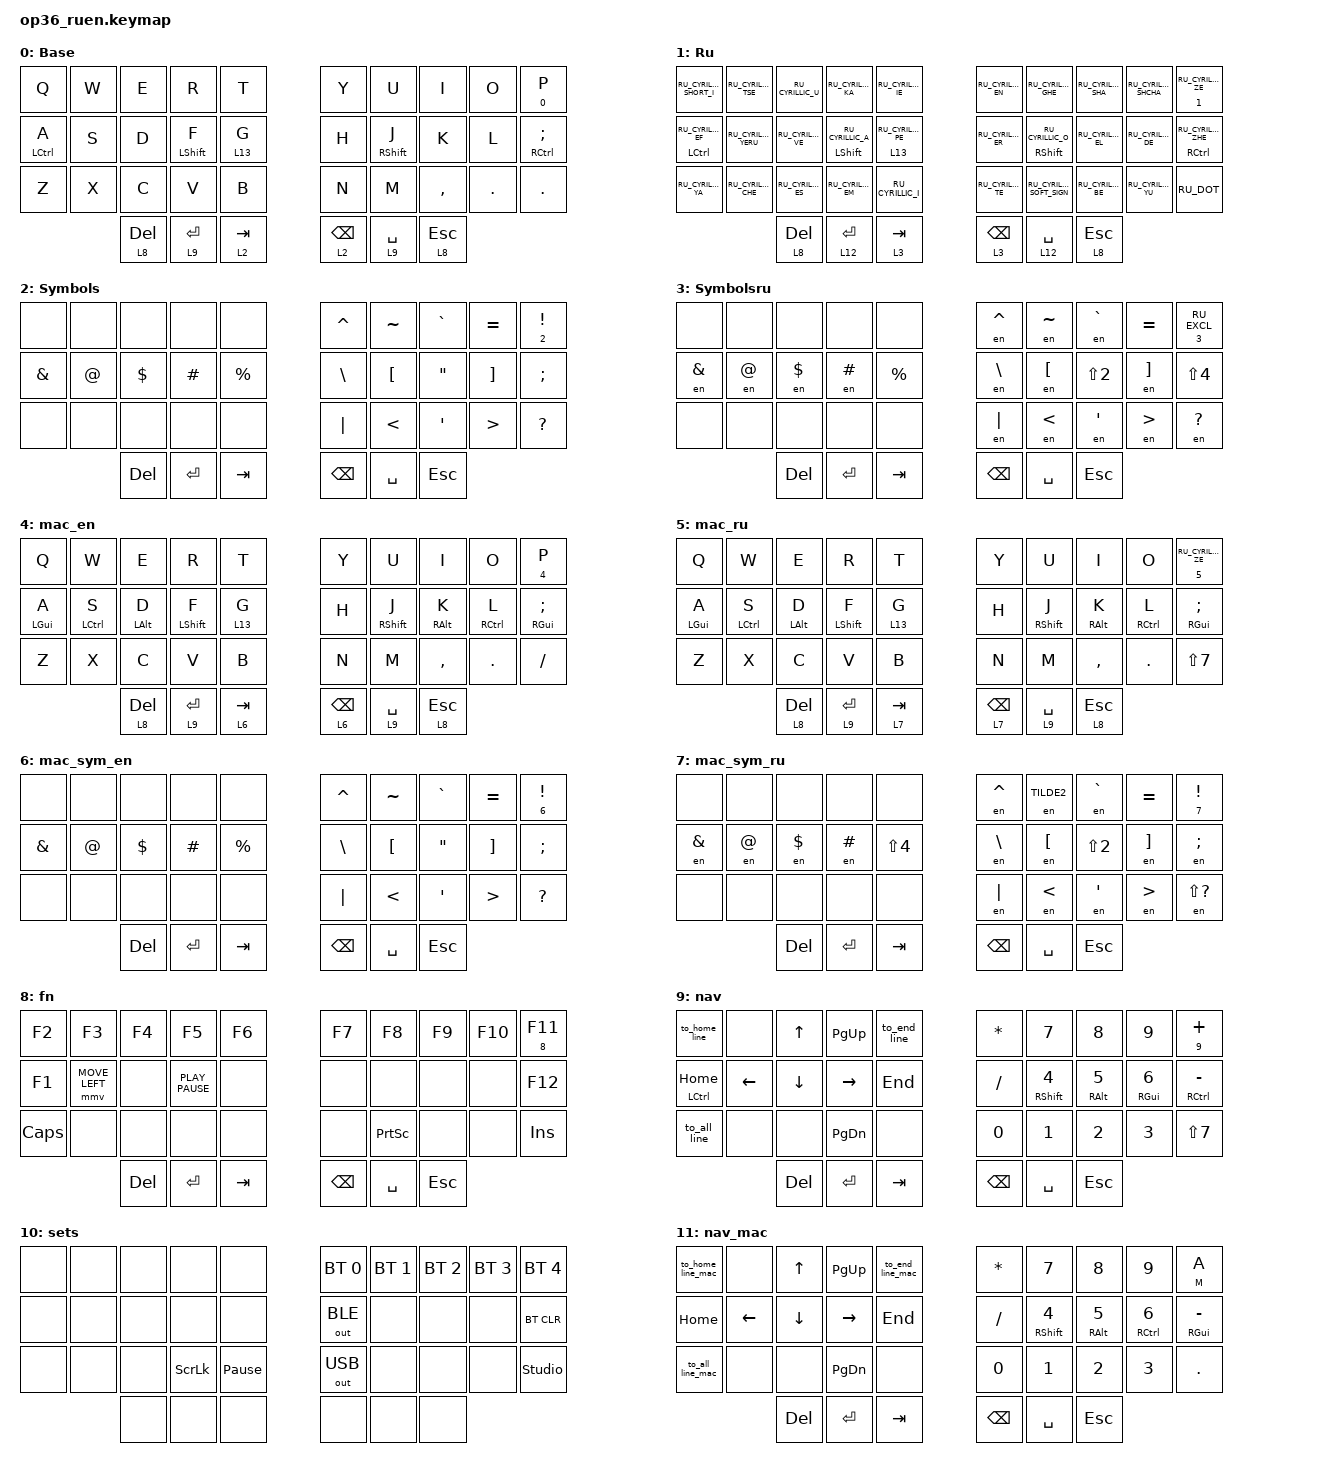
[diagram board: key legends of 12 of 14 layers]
#include "keys_ru.h"
#include "keys_ru.h"
#include <behaviors.dtsi>
#include <dt-bindings/zmk/bt.h>
#include <dt-bindings/zmk/keys.h>
#include <dt-bindings/zmk/outputs.h>
#include <dt-bindings/zmk/pointing.h>

&mt {
    quick-tap-ms = <200>;
    flavor = "tap-preferred";
    require-prior-idle-ms = <125>;
};

/ {
    behaviors {
        hml: home_row_mod_left {
            compatible = "zmk,behavior-hold-tap";
            #binding-cells = <2>;
            flavor = "balanced";
            require-prior-idle-ms = <100>;
            tapping-term-ms = <140>;
            quick-tap-ms = <120>;
            bindings = <&kp>, <&kp>;

            hold-trigger-key-positions = <5 6 7 8 9 15 16 17 18 19 25 26 27 28 29 33 34 35>;
            hold-trigger-on-release;
        };

        hmr: home_row_mod_right {
            compatible = "zmk,behavior-hold-tap";
            #binding-cells = <2>;
            flavor = "balanced";
            require-prior-idle-ms = <100>;
            tapping-term-ms = <140>;
            quick-tap-ms = <120>;
            bindings = <&kp>, <&kp>;

            hold-trigger-key-positions = <0 1 2 3 4 10 11 12 13 14 20 21 22 23 24 30 31 32>;
            hold-trigger-on-release;
        };
    };

    combos {
        compatible = "zmk,combos";

        kha {
            bindings = <&kp RU_CYRILLIC_HA>;
            key-positions = <8 7>;
            layers = <1 5>;
        };

        hrdsgn {
            bindings = <&kp RU_CYRILLIC_HARD_SIGN>;
            key-positions = <6 9>;
            layers = <1 5>;
        };

        cmben {
            bindings = <&layer_en>;
            key-positions = <2 1>;
            layers = <1>;
        };

        cmbru {
            bindings = <&layer_ru>;
            key-positions = <2 1>;
            layers = <0>;
        };

        to_mac {
            bindings = <&mac_layer_en>;
            key-positions = <35 33>;
        };

        to_base {
            bindings = <&layer_en>;
            key-positions = <30 32>;
        };

        cmd_mac_ru {
            bindings = <&mac_layer_ru>;
            key-positions = <1 2>;
            layers = <4>;
        };

        cmd_mac_en {
            bindings = <&mac_layer_en>;
            key-positions = <1 2>;
            layers = <5>;
        };

        ru_io {
            bindings = <&kp RU_CYRILLIC_IO>;
            key-positions = <3 2>;
            layers = <1>;
        };

        mac_ru_io {
            bindings = <&kp BACKSLASH>;
            key-positions = <3 2>;
            layers = <7 5>;
        };

        ru_ea {
            bindings = <&kp SINGLE_QUOTE>;
            key-positions = <6 7>;
            layers = <1 5 3 7>;
        };

        colon_en {
            bindings = <&kp COLON>;
            key-positions = <16 17>;
            layers = <0 2 4 6>;
        };

        colon_ru {
            bindings = <&kp RU_COLON>;
            key-positions = <16 17>;
            layers = <1 3>;
        };

        comma_en {
            bindings = <&kp COMMA>;
            key-positions = <26 27>;
            layers = <0 2 4 6 9>;
        };

        comma_ru {
            bindings = <&kp LS(SLASH)>;
            key-positions = <26 27>;
            layers = <1 3 12>;
        };

        to_layer_en {
            bindings = <&to 0>;
            key-positions = <1 2 3>;
            layers = <1>;
        };

        to_layer_mac_en {
            bindings = <&to 4>;
            key-positions = <1 2 3>;
            layers = <5>;
        };

        brace_left_en {
            bindings = <&kp LEFT_BRACE>;
            key-positions = <16 7>;
            layers = <0 2 6 4>;
        };

        brace_right_en {
            bindings = <&kp RIGHT_BRACE>;
            key-positions = <6 17>;
            layers = <0 2 4 6>;
        };

        brace_left_ru {
            bindings = <&en LEFT_BRACE>;
            key-positions = <16 7>;
            layers = <1 3 5 7>;
        };

        brace_right_ru {
            bindings = <&en RIGHT_BRACE>;
            key-positions = <6 17>;
            layers = <1 3 5 7>;
        };

        br_left {
            bindings = <&kp LS(NUMBER_9)>;
            key-positions = <26 17>;
        };

        br_right {
            bindings = <&kp LS(NUMBER_0)>;
            key-positions = <27 16>;
        };

        underscore {
            bindings = <&kp UNDER>;
            key-positions = <6 15>;
        };

        comma_mac_ru {
            bindings = <&kp LS(NUMBER_6)>;
            key-positions = <26 27>;
            layers = <5 7>;
        };

        colon_mac_ru {
            bindings = <&kp LS(NUMBER_5)>;
            key-positions = <16 17>;
            layers = <5 7>;
        };

        lt10 {
            bindings = <&mo 10>;
            key-positions = <30 31>;
        };

        Lalt {
            bindings = <&kp LEFT_ALT>;
            key-positions = <11 12>;
        };

        Ralt {
            bindings = <&kp RIGHT_ALT>;
            key-positions = <17 18>;
        };

        Lgui {
            bindings = <&kp LEFT_GUI>;
            key-positions = <21 22>;
        };

        Rgui {
            bindings = <&kp RIGHT_GUI>;
            key-positions = <27 28>;
        };
    };

    macros {
        to_ru: to_ru {
            compatible = "zmk,behavior-macro";
            #binding-cells = <0>;
            bindings = <&kp LG(SPACE)>;
            label = "TO_RU";
            wait-ms = <0>;
            tap-ms = <30>;
        };

        to_en: to_en {
            compatible = "zmk,behavior-macro";
            #binding-cells = <0>;
            bindings = <&kp LG(SPACE)>;
            label = "TO_EN";
            wait-ms = <0>;
            tap-ms = <30>;
        };

        layer_en: layer_en {
            compatible = "zmk,behavior-macro";
            #binding-cells = <0>;
            bindings = <&to 0 &to_en>;
            label = "LAYER_EN";
            wait-ms = <0>;
            tap-ms = <30>;
        };

        layer_ru: layer_ru {
            compatible = "zmk,behavior-macro";
            #binding-cells = <0>;
            bindings = <&to 1 &to_ru>;
            label = "LAYER_RU";
            tap-ms = <30>;
            wait-ms = <0>;
        };

        en: en {
            compatible = "zmk,behavior-macro-one-param";
            #binding-cells = <1>;
            bindings =
                <&to_en>,
                <&macro_press>,
                <&macro_param_1to1 &kp MACRO_PLACEHOLDER>,
                <&macro_pause_for_release>,
                <&macro_release>,
                <&macro_param_1to1 &kp MACRO_PLACEHOLDER>,
                <&macro_tap>,
                <&to_ru>;

            label = "EN";
            wait-ms = <0>;
            tap-ms = <30>;
        };

        mac_layer_ru: mac_layer_ru {
            compatible = "zmk,behavior-macro";
            #binding-cells = <0>;
            bindings = <&to 5 &to_ru>;
            label = "MAC_LAYER_RU";
        };

        mac_layer_en: mac_layer_en {
            compatible = "zmk,behavior-macro";
            #binding-cells = <0>;
            bindings = <&to 4 &to_en>;
            label = "MAC_LAYER_EN";
        };

        to_home_line: to_home_line {
            compatible = "zmk,behavior-macro";
            #binding-cells = <0>;
            bindings = <&kp LS(HOME)>, <&macro_wait_time 50>, <&kp LC(C)>;

            label = "TO_HOME_LINE";
        };

        to_home_line_mac: to_home_line_mac {
            compatible = "zmk,behavior-macro";
            #binding-cells = <0>;
            bindings = <&kp LS(HOME)>, <&macro_wait_time 50>, <&kp LG(C)>;

            label = "TO_HOME_LINE_MAC";
        };

        to_end_line: to_end_line {
            compatible = "zmk,behavior-macro";
            #binding-cells = <0>;
            bindings = <&kp LS(END)>, <&macro_wait_time 50>, <&kp LC(C)>;

            label = "TO_END_LINE";
        };

        to_end_line_mac: to_end_line_mac {
            compatible = "zmk,behavior-macro";
            #binding-cells = <0>;
            bindings = <&kp LS(END)>, <&macro_wait_time 50>, <&kp LG(C)>;

            label = "TO_END_LINE_MAC";
        };

        to_all_line: to_all_line {
            compatible = "zmk,behavior-macro";
            #binding-cells = <0>;
            bindings =
                <&kp HOME>,
                <&macro_wait_time 50>,
                <&kp LS(END)>,
                <&macro_wait_time 50>,
                <&kp LC(C)>;

            label = "TO_ALL_LINE";
        };

        to_all_line_mac: to_all_line_mac {
            compatible = "zmk,behavior-macro";
            #binding-cells = <0>;
            bindings =
                <&kp HOME>,
                <&macro_wait_time 50>,
                <&kp LS(END)>,
                <&macro_wait_time 50>,
                <&kp LG(C)>;

            label = "TO_ALL_LINE_MAC";
        };

        code_block: code_block {
            compatible = "zmk,behavior-macro";
            #binding-cells = <0>;
            bindings =
                <&kp GRAVE &kp GRAVE &kp GRAVE>,
                <&macro_wait_time 50>,
                <&kp ENTER>,
                <&macro_wait_time 50>,
                <&kp GRAVE &kp GRAVE &kp GRAVE>,
                <&macro_wait_time 50>,
                <&kp UP>;

            label = "CODE_BLOCK";
        };
    };

    keymap {
        compatible = "zmk,keymap";

        en {
            bindings = <
  &kp Q         &kp W  &kp E  &kp R              &kp T                                      &kp Y        &kp U          &kp I      &kp O    &mt NUMBER_0 P
  &hml LCTRL A  &kp S  &kp D  &hml LEFT_SHIFT F  &lt 13 G                                   &kp H        &hmr RSHIFT J  &kp K      &kp L    &hmr RCTRL SEMICOLON
  &kp Z         &kp X  &kp C  &kp V              &kp B                                      &kp N        &kp M          &kp COMMA  &kp DOT  &kp DOT
                              &lt 8 DEL          &lt 9 ENTER  &lt 2 TAB    &lt 2 BACKSPACE  &lt 9 SPACE  &lt 8 ESC
            >;

            display-name = "Base";
        };

        ru {
            bindings = <
  &kp RU_CYRILLIC_SHORT_I    &kp RU_CYRILLIC_TSE   &kp RU_CYRILLIC_U   &kp RU_CYRILLIC_KA         &kp RU_CYRILLIC_IE                                   &kp RU_CYRILLIC_EN  &kp RU_CYRILLIC_GHE             &kp RU_CYRILLIC_SHA  &kp RU_CYRILLIC_SHCHA  &mt NUMBER_1 RU_CYRILLIC_ZE
  &hml LCTRL RU_CYRILLIC_EF  &kp RU_CYRILLIC_YERU  &kp RU_CYRILLIC_VE  &hml LSHIFT RU_CYRILLIC_A  &lt 13 RU_CYRILLIC_PE                                &kp RU_CYRILLIC_ER  &hmr RIGHT_SHIFT RU_CYRILLIC_O  &kp RU_CYRILLIC_EL   &kp RU_CYRILLIC_DE     &hmr RCTRL RU_CYRILLIC_ZHE
  &kp RU_CYRILLIC_YA         &kp RU_CYRILLIC_CHE   &kp RU_CYRILLIC_ES  &kp RU_CYRILLIC_EM         &kp RU_CYRILLIC_I                                    &kp RU_CYRILLIC_TE  &kp RU_CYRILLIC_SOFT_SIGN       &kp RU_CYRILLIC_BE   &kp RU_CYRILLIC_YU     &kp RU_DOT
                                                                       &lt 8 DEL                  &lt 12 ENTER           &lt 3 TAB    &lt 3 BACKSPACE  &lt 12 SPACE        &lt 8 ESC
            >;

            display-name = "Ru";
        };

        sym_en {
            bindings = <
  &none          &none        &none       &none     &none                                  &kp CARET      &kp TILDE         &kp GRAVE          &kp EQUAL          &mt NUMBER_2 EXCLAMATION
  &kp AMPERSAND  &kp AT_SIGN  &kp DOLLAR  &kp HASH  &kp PERCENT                            &kp BACKSLASH  &kp LEFT_BRACKET  &kp DOUBLE_QUOTES  &kp RIGHT_BRACKET  &kp SEMICOLON
  &none          &none        &none       &none     &none                                  &kp PIPE       &kp LESS_THAN     &kp APOSTROPHE     &kp GREATER_THAN   &kp QUESTION
                                          &kp DEL   &kp ENTER    &kp TAB    &kp BACKSPACE  &kp SPACE      &kp ESC
            >;

            display-name = "Symbols";
        };

        sym_ru {
            bindings = <
  &none          &none        &none       &none     &none                                  &en CARET      &en TILDE         &en GRAVE         &kp EQUAL          &mt NUMBER_3 RU_EXCL
  &en AMPERSAND  &en AT_SIGN  &en DOLLAR  &en HASH  &kp PERCENT                            &en BACKSLASH  &en LEFT_BRACKET  &kp LS(NUMBER_2)  &en RIGHT_BRACKET  &kp LS(NUMBER_4)
  &none          &none        &none       &none     &none                                  &en PIPE       &en LESS_THAN     &en SINGLE_QUOTE  &en GREATER_THAN   &en QUESTION
                                          &kp DEL   &kp ENTER    &kp TAB    &kp BACKSPACE  &kp SPACE      &kp ESC
            >;

            display-name = "Symbolsru";
        };

        mac_en {
            bindings = <
  &kp Q            &kp W         &kp E            &kp R              &kp T                                      &kp Y        &kp U               &kp I             &kp O         &mt NUMBER_4 P
  &hml LEFT_GUI A  &hml LCTRL S  &hml LEFT_ALT D  &hml LEFT_SHIFT F  &lt 13 G                                   &kp H        &hmr RIGHT_SHIFT J  &hmr RIGHT_ALT K  &hmr RCTRL L  &hmr RIGHT_GUI SEMI
  &kp Z            &kp X         &kp C            &kp V              &kp B                                      &kp N        &kp M               &kp COMMA         &kp DOT       &kp FSLH
                                                  &lt 8 DEL          &lt 9 ENTER  &lt 6 TAB    &lt 6 BACKSPACE  &lt 9 SPACE  &lt 8 ESC
            >;
        };

        mac_ru {
            bindings = <
  &kp Q            &kp W         &kp E            &kp R              &kp T                                      &kp Y        &kp U               &kp I             &kp O         &mt NUMBER_5 RU_CYRILLIC_ZE
  &hml LEFT_GUI A  &hml LCTRL S  &hml LEFT_ALT D  &hml LEFT_SHIFT F  &lt 13 G                                   &kp H        &hmr RIGHT_SHIFT J  &hmr RIGHT_ALT K  &hmr RCTRL L  &hmr RIGHT_GUI SEMI
  &kp Z            &kp X         &kp C            &kp V              &kp B                                      &kp N        &kp M               &kp COMMA         &kp DOT       &kp LS(NUMBER_7)
                                                  &lt 8 DEL          &lt 9 ENTER  &lt 7 TAB    &lt 7 BACKSPACE  &lt 9 SPACE  &lt 8 ESC
            >;
        };

        mac_sym_en {
            bindings = <
  &none          &none        &none       &none     &none                                  &kp CARET      &kp TILDE         &kp GRAVE          &kp EQUAL          &mt NUMBER_6 EXCLAMATION
  &kp AMPERSAND  &kp AT_SIGN  &kp DOLLAR  &kp HASH  &kp PERCENT                            &kp BACKSLASH  &kp LEFT_BRACKET  &kp DOUBLE_QUOTES  &kp RIGHT_BRACKET  &kp SEMICOLON
  &none          &none        &none       &none     &none                                  &kp PIPE       &kp LESS_THAN     &kp APOSTROPHE     &kp GREATER_THAN   &kp QUESTION
                                          &kp DEL   &kp ENTER    &kp TAB    &kp BACKSPACE  &kp SPACE      &kp ESC
            >;
        };

        mac_sym_ru {
            bindings = <
  &none          &none        &none       &none     &none                                       &en CARET      &en TILDE2        &en GRAVE         &kp EQUAL          &mt NUMBER_7 EXCLAMATION
  &en AMPERSAND  &en AT_SIGN  &en DOLLAR  &en HASH  &kp LS(NUMBER_4)                            &en BACKSLASH  &en LEFT_BRACKET  &kp LS(NUMBER_2)  &en RIGHT_BRACKET  &en SEMICOLON
  &none          &none        &none       &none     &none                                       &en PIPE       &en LESS_THAN     &en SINGLE_QUOTE  &en GREATER_THAN   &en LS(QUESTION)
                                          &kp DEL   &kp ENTER         &kp TAB    &kp BACKSPACE  &kp SPACE      &kp ESC
            >;
        };

        fn {
            bindings = <
  &kp F2    &kp F3          &kp F4  &kp F5            &kp F6                               &kp F7     &kp F8           &kp F9  &kp F10  &mt NUMBER_8 F11
  &kp F1    &mmv MOVE_LEFT  &none   &kp K_PLAY_PAUSE  &none                                &none      &none            &none   &none    &kp F12
  &kp CAPS  &none           &none   &none             &none                                &none      &kp PRINTSCREEN  &none   &none    &kp INSERT
                                    &kp DEL           &kp ENTER  &kp TAB    &kp BACKSPACE  &kp SPACE  &kp ESC
            >;
        };

        nav {
            bindings = <
  &to_home_line    &none     &kp UP    &kp PAGE_UP    &to_end_line                            &kp ASTERISK  &kp N7                     &kp N8                   &kp N9                   &mt NUMBER_9 PLUS
  &hml LCTRL HOME  &kp LEFT  &kp DOWN  &kp RIGHT      &kp END                                 &kp SLASH     &hmr RIGHT_SHIFT NUMBER_4  &hmr RIGHT_ALT NUMBER_5  &hmr RIGHT_GUI NUMBER_6  &hmr RCTRL MINUS
  &to_all_line     &none     &none     &kp PAGE_DOWN  &none                                   &kp N0        &kp N1                     &kp N2                   &kp N3                   &kp LS(NUMBER_7)
                                       &kp DEL        &kp ENTER     &kp TAB    &kp BACKSPACE  &kp SPACE     &kp ESC
            >;
        };

        sets {
            bindings = <
  &none  &none  &none  &none           &none                            &bt BT_SEL 0  &bt BT_SEL 1  &bt BT_SEL 2  &bt BT_SEL 3  &bt BT_SEL 4
  &none  &none  &none  &none           &none                            &out OUT_BLE  &none         &none         &none         &bt BT_CLR
  &none  &none  &none  &kp SCROLLLOCK  &kp PAUSE_BREAK                  &out OUT_USB  &none         &none         &none         &studio_unlock
                       &none           &none            &none    &none  &none         &none
            >;
        };

        nav_mac {
            bindings = <
  &to_home_line_mac  &none     &kp UP    &kp PAGE_UP    &to_end_line_mac                            &kp STAR   &kp N7                     &kp N8                   &kp N9               &mt M A
  &kp HOME           &kp LEFT  &kp DOWN  &kp RIGHT      &kp END                                     &kp SLASH  &hmr RIGHT_SHIFT NUMBER_4  &hmr RIGHT_ALT NUMBER_5  &hmr RCTRL NUMBER_6  &hmr RIGHT_GUI MINUS
  &to_all_line_mac   &none     &none     &kp PAGE_DOWN  &none                                       &kp N0     &kp N1                     &kp N2                   &kp N3               &kp DOT
                                         &kp DEL        &kp ENTER         &kp TAB    &kp BACKSPACE  &kp SPACE  &kp ESC
            >;
        };

        nav_ru {
            bindings = <
  &to_home_line    &none     &kp UP    &kp PAGE_UP    &to_end_line                            &en ASTERISK  &kp N7                     &kp N8                   &kp N9                   &mt NUMBER_9 PLUS
  &hml LCTRL HOME  &kp LEFT  &kp DOWN  &kp RIGHT      &kp END                                 &kp RU_SLASH  &hmr RIGHT_SHIFT NUMBER_4  &hmr RIGHT_ALT NUMBER_5  &hmr RIGHT_GUI NUMBER_6  &hmr RCTRL MINUS
  &to_all_line     &none     &none     &kp PAGE_DOWN  &none                                   &kp N0        &kp N1                     &kp N2                   &kp N3                   &kp RU_DOT
                                       &kp DEL        &kp ENTER     &kp TAB    &kp BACKSPACE  &kp SPACE     &kp ESC
            >;
        };

        revers {
            bindings = <
  &none  &none  &none  &none       &none                              &none  &none  &none  &none  &none
  &none  &none  &none  &none       &none                              &none  &none  &none  &none  &none
  &none  &none  &none  &none       &none                              &none  &none  &none  &none  &none
                       &kp ESCAPE  &kp SPACE  &kp BACKSPACE    &none  &none  &none
            >;
        };
    };
};
